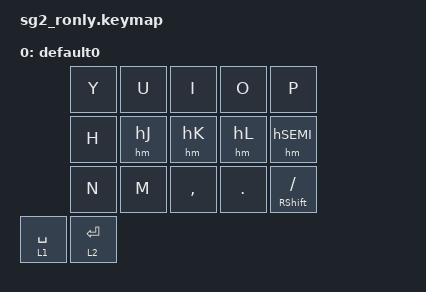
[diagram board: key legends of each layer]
#include <behaviors.dtsi>
#include <dt-bindings/zmk/keys.h>
#include <dt-bindings/zmk/bt.h>
#include <dt-bindings/zmk/outputs.h>
#include <dt-bindings/zmk/pointing.h>

#define hA    LGUI   A
#define hS    LALT   S
#define hD    LSHIFT D
#define hF    LCTRL  F
#define hJ    RCTRL  J
#define hK    RSHIFT K
#define hL    RALT   L
#define hSEMI RGUI   SEMI

/ {
    behaviors {

        hm: homerow_mods {
            compatible = "zmk,behavior-hold-tap";
            #binding-cells = <2>;
            tapping-term-ms = <200>;
            quick-tap-ms = <0>;
            flavor = "tap-preferred";
            bindings = <&kp>, <&kp>;
        };

    };

    keymap {
        compatible = "zmk,keymap";

        default0 { bindings = <
//               ╭── 40      ──┬── 41    ──┬── 42    ──┬── 43   ──┬── 44       ──╮
                 &kp Y         &kp U       &kp I       &kp O      &kp P
//               ├── 45      ──┼── 46    ──┼── 47    ──┼── 48   ──┼── 49       ──┤
                 &kp H         &hm hJ      &hm hK      &hm hL     &hm hSEMI
//               ├── 50      ──┼── 51    ──┼── 52    ──┼── 53   ──┼── 54       ──┤
                 &kp N         &kp M       &kp COMMA   &kp DOT    &hm RSHFT FSLH
//   ╭── 55    ──┼── 56      ──┼──       ──┴──       ──┴──      ──┴──          ──╯
     &lt 1 SPACE &lt 2 RET     >; };
//   ╰──       ──┴──         ──╯

    };
};
